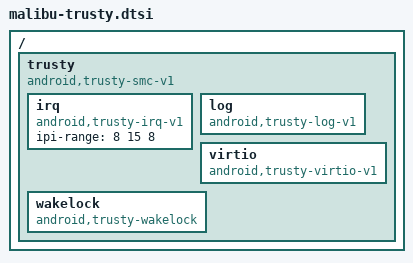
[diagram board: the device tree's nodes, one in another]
// SPDX-License-Identifier: GPL-2.0-only
/*
 * Trusty device tree source
 *
 * Copyright 2025 Google LLC
 */

/ {
	trusty: trusty {
		compatible = "android,trusty-smc-v1";

		irq {
			compatible = "android,trusty-irq-v1";
			ipi-range = <8 15 8>;
		};

		log {
			compatible = "android,trusty-log-v1";
		};

		virtio {
			compatible = "android,trusty-virtio-v1";
		};

		wakelock {
			compatible = "android,trusty-wakelock";
		};
	};
};
